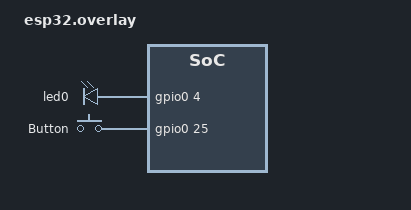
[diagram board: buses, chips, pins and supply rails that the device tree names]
/ {
	leds {
		compatible = "gpio-leds";
		led0: led_0 {
			gpios = <&gpio0 4 GPIO_ACTIVE_HIGH>;
		};
	};

	buttons {
		compatible = "gpio-keys";
		button0: button_0 {
			gpios = <&gpio0 25 GPIO_ACTIVE_HIGH>;
			label = "Button";
		};
	};

	aliases {
		l0 = &led0;
	};
};

